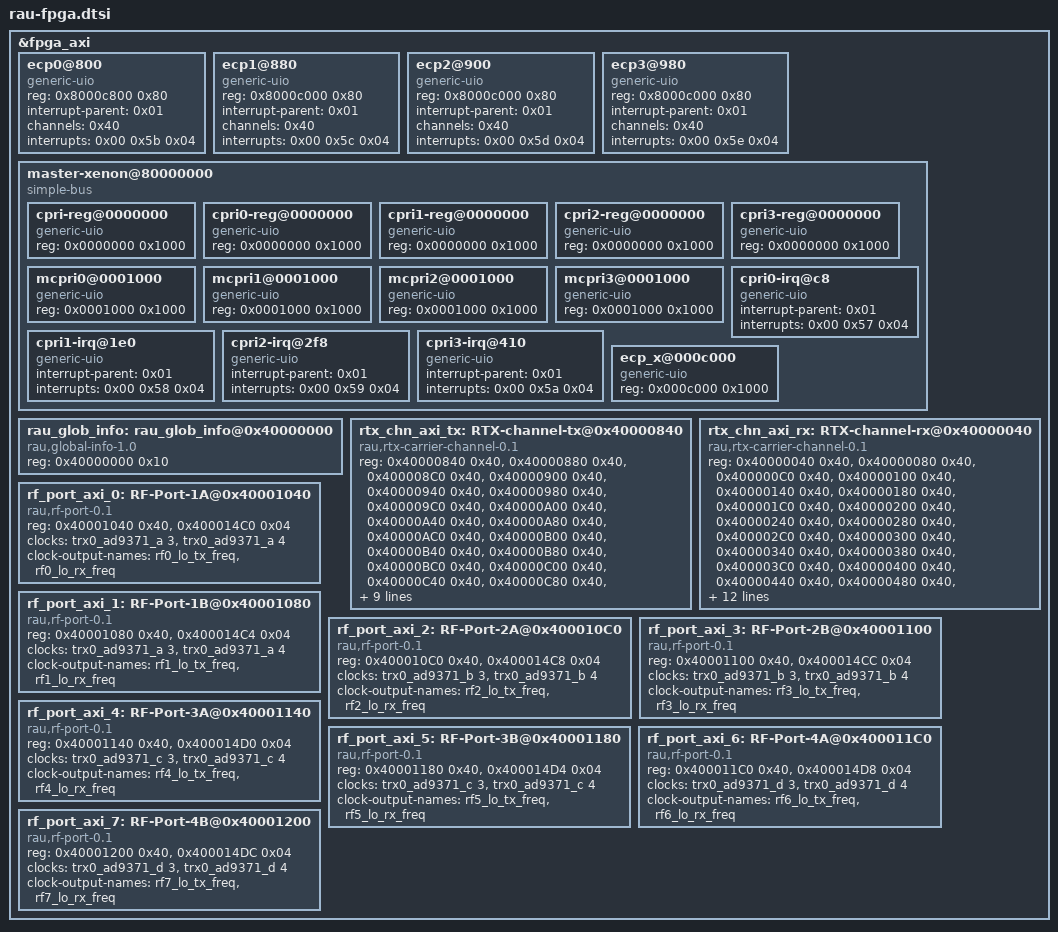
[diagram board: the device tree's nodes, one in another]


&fpga_axi {

	ecp0@800 {
		compatible = "generic-uio";
		reg = < 0x8000c800 0x80 >;
		interrupt-parent = < 0x01 >;
		channels = < 0x40 >;
		interrupts = < 0x00 0x5b 0x04 >;
	};

	ecp1@880 {
		compatible = "generic-uio";
		reg = < 0x8000c000 0x80 >;
		interrupt-parent = < 0x01 >;
		channels = < 0x40 >;
		interrupts = < 0x00 0x5c 0x04 >;
	};

	ecp2@900 {
		compatible = "generic-uio";
		reg = < 0x8000c000 0x80 >;
		interrupt-parent = < 0x01 >;
		channels = < 0x40 >;
		interrupts = < 0x00 0x5d 0x04 >;
	};

	ecp3@980 {
		compatible = "generic-uio";
		reg = < 0x8000c000 0x80 >;
		interrupt-parent = < 0x01 >;
		channels = < 0x40 >;
		interrupts = < 0x00 0x5e 0x04 >;
	};

	master-xenon@80000000 {
		compatible = "simple-bus";
		ranges = < 0x0000000 0x80000000 0x10000000 >;
		#address-cells = < 0x01 >;
		#size-cells = < 0x01 >;

		cpri-reg@0000000 {
			compatible = "generic-uio";
			reg = < 0x0000000 0x1000 >;
		};

		cpri0-reg@0000000 {
			compatible = "generic-uio";
			reg = < 0x0000000 0x1000 >;
		};

		cpri1-reg@0000000 {
			compatible = "generic-uio";
			reg = < 0x0000000 0x1000 >;
		};

		cpri2-reg@0000000 {
			compatible = "generic-uio";
			reg = < 0x0000000 0x1000 >;
		};

		cpri3-reg@0000000 {
			compatible = "generic-uio";
			reg = < 0x0000000 0x1000 >;
		};

		mcpri0@0001000 {
			compatible = "generic-uio";
			reg = < 0x0001000 0x1000 >;
		};

		mcpri1@0001000 {
			compatible = "generic-uio";
			reg = < 0x0001000 0x1000 >;
		};

		mcpri2@0001000 {
			compatible = "generic-uio";
			reg = < 0x0001000 0x1000 >;
		};

		mcpri3@0001000 {
			compatible = "generic-uio";
			reg = < 0x0001000 0x1000 >;
		};

		cpri0-irq@c8 {
			compatible = "generic-uio";
			interrupt-parent = < 0x01 >;
			interrupts = < 0x00 0x57 0x04 >;
		};

		cpri1-irq@1e0 {
			compatible = "generic-uio";
			interrupt-parent = < 0x01 >;
			interrupts = < 0x00 0x58 0x04 >;
		};

		cpri2-irq@2f8 {
			compatible = "generic-uio";
			interrupt-parent = < 0x01 >;
			interrupts = < 0x00 0x59 0x04 >;
		};

		cpri3-irq@410 {
			compatible = "generic-uio";
			interrupt-parent = < 0x01 >;
			interrupts = < 0x00 0x5a 0x04 >;
		};

		ecp_x@000c000 {
			compatible = "generic-uio";
			reg = < 0x000c000 0x1000 >;
		};
	};


	rau_glob_info: rau_glob_info@0x40000000 {
		compatible = "rau,global-info-1.0";
		reg = <0x40000000 0x10>;
	};

	//-------------- RTX carrier channel --------------------------
	////-------------- UL TX  (有限制)-------------------
	rtx_chn_axi_tx: RTX-channel-tx@0x40000840 {
		#clock-cells = <1>;
		compatible = "rau,rtx-carrier-channel-0.1";
		//reg = <0x40000840 0x800>;//总共
		reg = <0x40000840 0x40>,
		      <0x40000880 0x40>,
		      <0x400008C0 0x40>,
		      <0x40000900 0x40>,
		      <0x40000940 0x40>,
		      <0x40000980 0x40>,
		      <0x400009C0 0x40>,
		      <0x40000A00 0x40>,
		      <0x40000A40 0x40>,
		      <0x40000A80 0x40>,
		      <0x40000AC0 0x40>,
		      <0x40000B00 0x40>,
		      <0x40000B40 0x40>,
		      <0x40000B80 0x40>,
		      <0x40000BC0 0x40>,
		      <0x40000C00 0x40>,
		      <0x40000C40 0x40>,
		      <0x40000C80 0x40>,
		      <0x40000CC0 0x40>,
		      <0x40000D00 0x40>,
		      <0x40000D40 0x40>,
		      <0x40000D80 0x40>,
		      <0x40000DC0 0x40>,
		      <0x40000E00 0x40>,
		      <0x40000E40 0x40>,
		      <0x40000E80 0x40>,
		      <0x40000EC0 0x40>,
		      <0x40000F00 0x40>,
		      <0x40000F40 0x40>,
		      <0x40000F80 0x40>,
		      <0x40000FC0 0x40>,
		      <0x40001000 0x40>,
		      <0x40001488 0x08>;// bw rst busy

		      dfe,node-is-uplink;
	};

	////-------------- DL RX  --------------------------

	rtx_chn_axi_rx: RTX-channel-rx@0x40000040 {
		#clock-cells = <1>;
		compatible = "rau,rtx-carrier-channel-0.1";
		//reg = <0x40000040 0x800>;//总共
		reg = <0x40000040 0x40>,
		      <0x40000080 0x40>,
		      <0x400000C0 0x40>,
		      <0x40000100 0x40>,
		      <0x40000140 0x40>,
		      <0x40000180 0x40>,
		      <0x400001C0 0x40>,
		      <0x40000200 0x40>,
		      <0x40000240 0x40>,
		      <0x40000280 0x40>,
		      <0x400002C0 0x40>,
		      <0x40000300 0x40>,
		      <0x40000340 0x40>,
		      <0x40000380 0x40>,
		      <0x400003C0 0x40>,
		      <0x40000400 0x40>,
		      <0x40000440 0x40>,
		      <0x40000480 0x40>,
		      <0x400004C0 0x40>,
		      <0x40000500 0x40>,
		      <0x40000540 0x40>,
		      <0x40000580 0x40>,
		      <0x400005C0 0x40>,
		      <0x40000600 0x40>,
		      <0x40000640 0x40>,
		      <0x40000680 0x40>,
		      <0x400006C0 0x40>,
		      <0x40000700 0x40>,
		      <0x40000740 0x40>,
		      <0x40000780 0x40>,
		      <0x400007C0 0x40>,
		      <0x40000800 0x40>,
		      <0x40001480 0x08>;// bw rst busy

		clocks = <&rf_port_axi_7 0>, <&rf_port_axi_6 0>, <&rf_port_axi_5 0>, <&rf_port_axi_4 0>,
		         <&rf_port_axi_3 0>, <&rf_port_axi_2 0>, <&rf_port_axi_1 0>, <&rf_port_axi_0 0>;
		clock-names = "dl_lo_1a","dl_lo_1b","dl_lo_2a","dl_lo_2b",
			      "dl_lo_3a","dl_lo_3b","dl_lo_4a","dl_lo_4b";


	};


	rf_port_axi_0: RF-Port-1A@0x40001040 {
		#clock-cells = <1>;
		compatible = "rau,rf-port-0.1";
		reg = <0x40001040 0x40>,
		      <0x400014C0 0x04>; // Port_SW_Control

		clocks = <&trx0_ad9371_a 3>, <&trx0_ad9371_a 4> ;
		clock-names = "lo_rx_freq","lo_tx_freq";

		clock-output-names = "rf0_lo_tx_freq", "rf0_lo_rx_freq";

	};

	rf_port_axi_1: RF-Port-1B@0x40001080 {
		#clock-cells = <1>;
		compatible = "rau,rf-port-0.1";
		reg = <0x40001080 0x40>,
		      <0x400014C4 0x04>; // Port_SW_Control

		clocks = <&trx0_ad9371_a 3>, <&trx0_ad9371_a 4> ;
		clock-names = "lo_rx_freq","lo_tx_freq";

		clock-output-names = "rf1_lo_tx_freq", "rf1_lo_rx_freq";
	};

	rf_port_axi_2: RF-Port-2A@0x400010C0 {
		#clock-cells = <1>;
		compatible = "rau,rf-port-0.1";
		reg = <0x400010C0 0x40>,
		      <0x400014C8 0x04>; // Port_SW_Control

		clocks = <&trx0_ad9371_b 3>, <&trx0_ad9371_b 4> ;
		clock-names = "lo_rx_freq","lo_tx_freq";

		clock-output-names = "rf2_lo_tx_freq", "rf2_lo_rx_freq";
	};

	rf_port_axi_3: RF-Port-2B@0x40001100 {
		#clock-cells = <1>;
		compatible = "rau,rf-port-0.1";
		reg = <0x40001100 0x40>,
		      <0x400014CC 0x04>; // Port_SW_Control

		clocks = <&trx0_ad9371_b 3>, <&trx0_ad9371_b 4> ;
		clock-names = "lo_rx_freq","lo_tx_freq";

		clock-output-names = "rf3_lo_tx_freq", "rf3_lo_rx_freq";
	};


	//-------------- port4 ~ port7 --------------------------

	rf_port_axi_4: RF-Port-3A@0x40001140 {
		#clock-cells = <1>;
		compatible = "rau,rf-port-0.1";
		reg = <0x40001140 0x40>,
		      <0x400014D0 0x04>; // Port_SW_Control

		clocks = <&trx0_ad9371_c 3>, <&trx0_ad9371_c 4> ;
		clock-names = "lo_rx_freq","lo_tx_freq";

		clock-output-names = "rf4_lo_tx_freq", "rf4_lo_rx_freq";

	};

	rf_port_axi_5: RF-Port-3B@0x40001180 {
		#clock-cells = <1>;
		compatible = "rau,rf-port-0.1";
		reg = <0x40001180 0x40>,
		      <0x400014D4 0x04>; // Port_SW_Control

		clocks = <&trx0_ad9371_c 3>, <&trx0_ad9371_c 4> ;
		clock-names = "lo_rx_freq","lo_tx_freq";

		clock-output-names = "rf5_lo_tx_freq", "rf5_lo_rx_freq";
	};

	rf_port_axi_6: RF-Port-4A@0x400011C0 {
		#clock-cells = <1>;
		compatible = "rau,rf-port-0.1";
		reg = <0x400011C0 0x40>,
		      <0x400014D8 0x04>; // Port_SW_Control

		clocks = <&trx0_ad9371_d 3>, <&trx0_ad9371_d 4> ;
		clock-names = "lo_rx_freq","lo_tx_freq";

		clock-output-names = "rf6_lo_tx_freq", "rf6_lo_rx_freq";
	};

	rf_port_axi_7: RF-Port-4B@0x40001200 {
		#clock-cells = <1>;
		compatible = "rau,rf-port-0.1";
		reg = <0x40001200 0x40>,
		      <0x400014DC 0x04>; // Port_SW_Control

		clocks = <&trx0_ad9371_d 3>, <&trx0_ad9371_d 4> ;
		clock-names = "lo_rx_freq","lo_tx_freq";

		clock-output-names = "rf7_lo_tx_freq", "rf7_lo_rx_freq";
	};



};

